# STM32H523 register map
File version: 1.2
CPU: CM33 r0p0, little endian, MPU, FPU, 4 interrupt priority bits
Registers are 32-bit, read-write, reset 0x0 unless marked. A register's access mark holds for its fields unless they carry their own. Offsets are from the block's base; [hi:lo] are bit positions; {n}, {i} and the like mark numbered series.

## TAMP — TAMP register block
Base 0x44007C00
Same registers: TAMP_S 0x54007C00
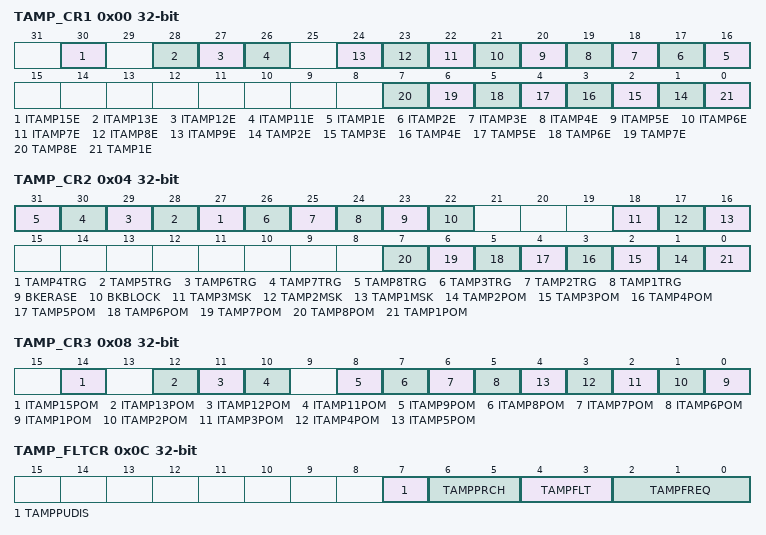
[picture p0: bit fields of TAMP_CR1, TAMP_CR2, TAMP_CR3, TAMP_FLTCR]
0x00 TAMP_CR1 — TAMP control register 1
  [30] ITAMP15E — Internal tamper 15 enable
    0=Internal tamper 15 disabled; 1=Internal tamper 15 enabled
  [28] ITAMP13E — Internal tamper 13 enable
    0=Internal tamper 13 disabled; 1=Internal tamper 13 enabled
  [27] ITAMP12E — Internal tamper 12 enable
    0=Internal tamper 12 disabled; 1=Internal tamper 12 enabled
  [26] ITAMP11E — Internal tamper 11 enable
    0=Internal tamper 11 disabled; 1=Internal tamper 11 enabled
  [n+15] ITAMP{n}E (n=1..9) — Internal tamper {n} enable
    0=Internal tamper {n} disabled; 1=Internal tamper {n} enabled
  [n-1] TAMP{n}E (n=2..8) — Tamper detection on TAMP_IN{n} enableless thansup>(1)less than/sup>
    0=Tamper detection on TAMP_IN{n} is disabled; 1=Tamper detection on TAMP_IN{n} is enabled
  [0] TAMP1E — Tamper detection on TAMP_IN1 enable
    0=Tamper detection on TAMP_IN1 is disabled; 1=Tamper detection on TAMP_IN1 is enabled
0x04 TAMP_CR2 — TAMP control register 2
  [n+23] TAMP{n}TRG (n=4..8) — Active level for tamper {n} input (active mode disabled)
    0=If TAMPFLT different to 00 tamper {n} input staying low triggers a tamper detection event; 1=If TAMPFLT different to 00 tamper {n} input staying high triggers a tamper detection event
  [26] TAMP3TRG — Active level for tamper 3 input
    0=If TAMPFLT different to 00 tamper 3 input staying low triggers a tamper detection event; 1=If TAMPFLT different to 00 tamper 3 input staying high triggers a tamper detection event
  [25] TAMP2TRG — Active level for tamper 2 input
    0=If TAMPFLT different to 00 tamper 2 input staying low triggers a tamper detection event; 1=If TAMPFLT different to 00 tamper 2 input staying high triggers a tamper detection event
  [24] TAMP1TRG — Active level for tamper 1 input
    0=If TAMPFLT different to 00 tamper 1 input staying low triggers a tamper detection event; 1=If TAMPFLT different to 00 tamper 1 input staying high triggers a tamper detection event
  [23] BKERASE wo — Backup registers and device secretsless thansup>(1)less than/sup> erase
  [22] BKBLOCK — Backup registers and device secretsless thansup>(1)less than/sup> access blocked
    0=backup registers and device secretsless thansup>(1)less than/sup> can be accessed if no tamper flag is set; 1=backup registers and device secretsless thansup>(1)less than/sup> cannot be accessed
  [18] TAMP3MSK — Tamper 3 mask
    0=Tamper 3 event generates a trigger event and TAMP3F must be cleared by software to allow next tamper event detection; 1=Tamper 3 event generates a trigger event
  [17] TAMP2MSK — Tamper 2 mask
    0=Tamper 2 event generates a trigger event and TAMP2F must be cleared by software to allow next tamper event detection; 1=Tamper 2 event generates a trigger event
  [16] TAMP1MSK — Tamper 1 mask
    0=Tamper 1 event generates a trigger event and TAMP1F must be cleared by software to allow next tamper event detection; 1=Tamper 1 event generates a trigger event
  [n-1] TAMP{n}POM (n=2..8) — Tamper {n} potential mode
    0=Tamper {n} event detection is in confirmed modeless thansup>(1)less than/sup>; 1=Tamper {n} event detection is in potential modeless thansup>(2)less than/sup>
  [0] TAMP1POM — Tamper 1 potential mode
    0=Tamper 1 event detection is in confirmed mode; 1=Tamper 1 event detection is in potential mode
0x08 TAMP_CR3 — TAMP control register 3
  [14] ITAMP15POM — Internal tamper 15 potential mode
    0=Internal tamper 15 event detection is in confirmed modeless thansup>(1)less than/sup>; 1=Internal tamper 15 event detection is in potential modeless thansup>(2)less than/sup>
  [12] ITAMP13POM — Internal tamper 13 potential mode
    0=Internal tamper 13 event detection is in confirmed modeless thansup>(1)less than/sup>; 1=Internal tamper 13 event detection is in potential modeless thansup>(2)less than/sup>
  [11] ITAMP12POM — Internal tamper 12 potential mode
    0=Internal tamper 12 event detection is in confirmed modeless thansup>(1)less than/sup>; 1=Internal tamper 12 event detection is in potential modeless thansup>(2)less than/sup>
  [10] ITAMP11POM — Internal tamper 11 potential mode
    0=Internal tamper 11 event detection is in confirmed modeless thansup>(1)less than/sup>; 1=Internal tamper 11 event detection is in potential modeless thansup>(2)less than/sup>
  [8] ITAMP9POM — Internal tamper 9 potential mode
    0=Internal tamper 9 event detection is in confirmed modeless thansup>(1)less than/sup>; 1=Internal tamper 9 event detection is in potential modeless thansup>(2)less than/sup>
  [7] ITAMP8POM — Internal tamper 8 potential mode
    0=Internal tamper 8 event detection is in confirmed modeless thansup>(1)less than/sup>; 1=Internal tamper 8 event detection is in potential modeless thansup>(2)less than/sup>
  [6] ITAMP7POM — Internal tamper 7 potential mode
    0=Internal tamper 7 event detection is in confirmed modeless thansup>(1)less than/sup>; 1=Internal tamper 7 event detection is in potential modeless thansup>(2)less than/sup>
  [5] ITAMP6POM — Internal tamper 6 potential mode
    0=Internal tamper 6 event detection is in confirmed mode; 1=Internal tamper 6 event detection is in potential mode
  [n-1] ITAMP{n}POM (n=1..5) — Internal tamper {n} potential mode
    0=Internal tamper {n} event detection is in confirmed modeless thansup>(1)less than/sup>; 1=Internal tamper {n} event detection is in potential modeless thansup>(2)less than/sup>
0x0C TAMP_FLTCR — TAMP filter control register
  [7] TAMPPUDIS — TAMP_INx pull-up disable
    0=Precharge TAMP_INx pins before sampling (enable internal pull-up); 1=Disable precharge of TAMP_INx pins
  [6:5] TAMPPRCH — TAMP_INx precharge duration
    0=1 RTCCLK cycle; 1=2 RTCCLK cycles; 2=4 RTCCLK cycles; 3=8 RTCCLK cycles
  [4:3] TAMPFLT — TAMP_INx filter count
    0=Tamper event is activated on edge of TAMP_INx input transitions to the active level (no internal pull-up on TAMP_INx input); 1=Tamper event is activated after 2 consecutive samples at the active level; 2=Tamper event is activated after 4 consecutive samples at the active level; 3=Tamper event is activated after 8 consecutive samples at the active level
  [2:0] TAMPFREQ — Tamper sampling frequency
    0=RTCCLK / 32768 (1 Hz when RTCCLK = 32768 Hz); 1=RTCCLK / 16384 (2 Hz when RTCCLK = 32768 Hz); 2=RTCCLK / 8192 (4 Hz when RTCCLK = 32768 Hz); 3=RTCCLK / 4096 (8 Hz when RTCCLK = 32768 Hz); 4=RTCCLK / 2048 (16 Hz when RTCCLK = 32768 Hz); 5=RTCCLK / 1024 (32 Hz when RTCCLK = 32768 Hz); 6=RTCCLK / 512 (64 Hz when RTCCLK = 32768 Hz); 7=RTCCLK / 256 (128 Hz when RTCCLK = 32768 Hz)
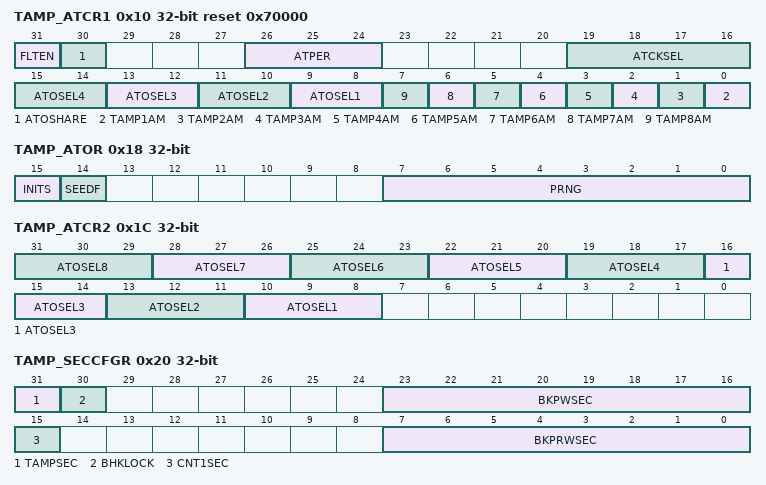
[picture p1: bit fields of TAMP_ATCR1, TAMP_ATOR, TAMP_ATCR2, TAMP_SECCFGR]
0x10 TAMP_ATCR1 reset 0x70000 — TAMP active tamper control register 1
  [31] FLTEN — Active tamper filter enable
    0=Active tamper filtering disable; 1=Active tamper filtering enable: a tamper event is detected when 2 comparison mismatches occur out of 4 consecutive samples
  [30] ATOSHARE — Active tamper output sharing
    0=Each active tamper input TAMP_INi is compared with its dedicated output TAMP_OUTi; 1=Each active tamper input TAMP_INi is compared with TAMPOUTSELi defined by ATOSELi bits
  [26:24] ATPER — Active tamper output change period
  [19:16] ATCKSEL — Active tamper RTC asynchronous prescaler clock selection
    0=RTCCLK is selected; 1=RTCCLK/2 is selected; 2=RTCCLK/4 is selected; 3=RTCCLK/8 is selected; 4=RTCCLK/16 is selected; 5=RTCCLK/32 is selected; 6=RTCCLK/64 is selected; 7=RTCCLK/128 is selected; 11=RTCCLK/2048 is selected when (PREDIV_A+1) = 128 and (PREDIV_S+1) is a multiple of 16
  [2n+7:2n+6] ATOSEL{n} (n=1..4) — Active tamper shared output {n} selection
    {v}=TAMPOUTSEL{n} = TAMP_OUT{v+1} (v=0..3)
  [n-1] TAMP{n}AM (n=1..8) — Tamper {n} active mode
    0=Tamper {n} detection mode is passive; 1=Tamper {n} detection mode is active
0x14 TAMP_ATSEEDR wo — TAMP active tamper seed register
  [31:0] SEED — Pseudo-random generator seed value
0x18 TAMP_ATOR ro — TAMP active tamper output register
  [15] INITS — Active tamper initialization status
  [14] SEEDF — Seed running flag
  [7:0] PRNG — Pseudo-random generator value
0x1C TAMP_ATCR2 — TAMP active tamper control register 2
  [3n+7:3n+5] ATOSEL{n} (n=1..8) — Active tamper shared output {n} selection
    {v}=TAMPOUTSEL{n} = TAMP_OUT{v+1} (v=0..7)
0x20 TAMP_SECCFGR — TAMP secure configuration register
  [31] TAMPSEC — Tamper protection (excluding monotonic counters and backup registers)
    0=Tamper configuration and interrupt can be written when the APB access is secure or nonsecure; 1=Tamper configuration and interrupt can be written only when the APB access is secure
  [30] BHKLOCK — Boot hardware key lock
    0=The Backup registers from TAMP_BKP0R to TAMP_BKP7R can be accessed according to the Protection zone they belong to; 1=The backup registers from TAMP_BKP0R to TAMP_BKP7R cannot be accessed neither in read nor in write (they are read as 0 and write ignore)
  [23:16] BKPWSEC — Backup registers write protection offset
  [15] CNT1SEC — Monotonic counter 1 secure protection
    0=Monotonic counter 1 (TAMP_COUNT1R) can be read and written when the APB access is secure or nonsecure; 1=Monotonic counter 1 (TAMP_COUNT1R) can be read and written only when the APB access is secure
  [7:0] BKPRWSEC — Backup registers read/write protection offset
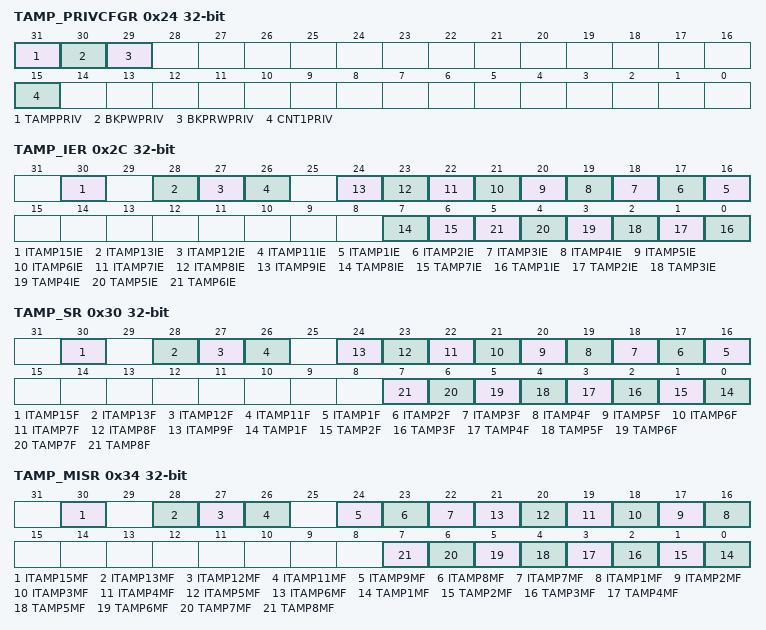
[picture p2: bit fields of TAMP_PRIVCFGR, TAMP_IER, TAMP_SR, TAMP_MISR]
0x24 TAMP_PRIVCFGR — TAMP privilege configuration register
  [31] TAMPPRIV — Tamper privilege protection (excluding backup registers)
    0=Tamper configuration and interrupt can be written with privileged or unprivileged access; 1=Tamper configuration and interrupt can be written only with privileged access
  [30] BKPWPRIV — Backup registers zone 2 privilege protection
    0=Backup registers zone 2 can be written with privileged or unprivileged access; 1=Backup registers zone 2 can be written only with privileged access
  [29] BKPRWPRIV — Backup registers zone 1 privilege protection
    0=Backup registers zone 1 can be read and written with privileged or unprivileged access; 1=Backup registers zone 1 can be read and written only with privileged access
  [15] CNT1PRIV — Monotonic counter 1 privilege protection
    0=Monotonic counter 1 (TAMP_COUNT1R) can be read and written when the APB access is privileged or non-privileged; 1=Monotonic counter 1 (TAMP_COUNT1R) can be read and written only when the APB access is privileged
0x2C TAMP_IER — TAMP interrupt enable register
  [30] ITAMP15IE — Internal tamper 15 interrupt enable
    0=Internal tamper 15 interrupt disabled; 1=Internal tamper 15 interrupt enabled
  [28] ITAMP13IE — Internal tamper 13 interrupt enable
    0=Internal tamper 13 interrupt disabled; 1=Internal tamper 13 interrupt enabled
  [27] ITAMP12IE — Internal tamper 12 interrupt enable
    0=Internal tamper 12 interrupt disabled; 1=Internal tamper 12 interrupt enabled
  [26] ITAMP11IE — Internal tamper 11 interrupt enable
    0=Internal tamper 11 interrupt disabled; 1=Internal tamper 11 interrupt enabled
  [n+15] ITAMP{n}IE (n=1..9) — Internal tamper {n} interrupt enable
    0=Internal tamper {n} interrupt disabled; 1=Internal tamper {n} interrupt enabled
  [7] TAMP8IE — Tamper 8 interrupt enable
    0=Tamper 8 interrupt disabled; 1=Tamper 8 interrupt enabled
  [6] TAMP7IE — Tamper 7interrupt enable
    0=Tamper 7 interrupt disabled; 1=Tamper 7interrupt enabled
  [n-1] TAMP{n}IE (n=1..6) — Tamper {n} interrupt enable
    0=Tamper {n} interrupt disabled; 1=Tamper {n} interrupt enabled
0x30 TAMP_SR — TAMP status register
  [30] ITAMP15F — Internal tamper 15 flag
  [28] ITAMP13F ro — Internal tamper 13 flag
  [27] ITAMP12F ro — Internal tamper 12 flag
  [26] ITAMP11F ro — Internal tamper 11 flag
  [n+15] ITAMP{n}F ro (n=1..9) — Internal tamper {n} flag
  [n-1] TAMP{n}F ro (n=1..8) — TAMP{n} detection flag
0x34 TAMP_MISR ro — TAMP nonsecure masked interrupt status register
  [30] ITAMP15MF — internal tamper 15 nonsecure interrupt masked flag
  [28] ITAMP13MF — internal tamper 13 nonsecure interrupt masked flag
  [27] ITAMP12MF — internal tamper 12 nonsecure interrupt masked flag
  [26] ITAMP11MF — internal tamper 11 nonsecure interrupt masked flag
  [24] ITAMP9MF — internal tamper 9 nonsecure interrupt masked flag
  [23] ITAMP8MF — Internal tamper 8 nonsecure interrupt masked flag
  [22] ITAMP7MF — Internal tamper 7 tamper nonsecure interrupt masked flag
  [n+15] ITAMP{n}MF (n=1..6) — Internal tamper {n} nonsecure interrupt masked flag
  [n-1] TAMP{n}MF (n=1..8) — TAMP{n} nonsecure interrupt masked flag
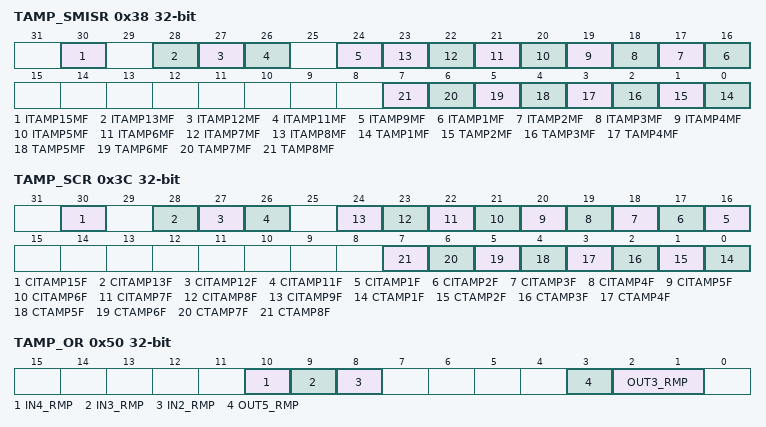
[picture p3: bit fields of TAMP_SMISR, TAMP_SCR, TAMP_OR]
0x38 TAMP_SMISR ro — TAMP secure masked interrupt status register
  [30] ITAMP15MF — internal tamper 15 secure interrupt masked flag
  [28] ITAMP13MF — internal tamper 13 secure interrupt masked flag
  [27] ITAMP12MF — internal tamper 12 secure interrupt masked flag
  [26] ITAMP11MF — internal tamper 11 secure interrupt masked flag
  [24] ITAMP9MF — internal tamper 9 secure interrupt masked flag
  [n+15] ITAMP{n}MF (n=1..8) — Internal tamper {n} secure interrupt masked flag
  [n-1] TAMP{n}MF (n=1..8) — TAMP{n} secure interrupt masked flag
0x3C TAMP_SCR wo — TAMP status clear register
  [30] CITAMP15F — Clear ITAMP15 detection flag
  [28] CITAMP13F — Clear ITAMP13 detection flag
  [27] CITAMP12F — Clear ITAMP12 detection flag
  [26] CITAMP11F — Clear ITAMP11 detection flag
  [n+15] CITAMP{n}F (n=1..9) — Clear ITAMP{n} detection flag
  [n-1] CTAMP{n}F (n=1..8) — Clear TAMP{n} detection flag
0x40 TAMP_COUNT1R ro — TAMP monotonic counter 1 register
  [31:0] COUNT — This register is read-only only and is incremented by one when a write access is done to this register.
0x50 TAMP_OR — TAMP option register
  [10] IN4_RMP — TAMP_IN4 mapping
    0=TAMP_IN4 is on PA2; 1=TAMP_IN4 is on PI11
  [9] IN3_RMP — TAMP_IN3 mapping
    0=TAMP_IN3 is on PC1; 1=TAMP_IN3 is on PE6
  [8] IN2_RMP — TAMP_IN2 mapping
    0=TAMP_IN2 is on PA0; 1=TAMP_IN2 is on PI8
  [3] OUT5_RMP — TAMP_OUT5 mapping
    0=TAMP_OUT5 is on PI11; 1=TAMP_OUT5 is on PC1
  [2:1] OUT3_RMP — TAMP_OUT3 mapping
    0=TAMP_OUT3 is on PC13; 1=TAMP_OUT3 is on PI8; 2=TAMP_OUT3 is on PE3; 3=TAMP_OUT3 is on PA2
0x54 TAMP_RPCFGR — TAMP resources protection configuration register
  [0] RPCFG0 — Configurable resource 0 protection
    0=Resource 0 is not included in the device secrets protected by TAMP peripheral; 1=Resource 0 is included in the device secrets protected by TAMP peripheral
{0x100+4i} TAMP_BKP{i}R (i=0..31) — TAMP backup {i} register
  [31:0] BKP — The application can write or read data to and from these registers.
